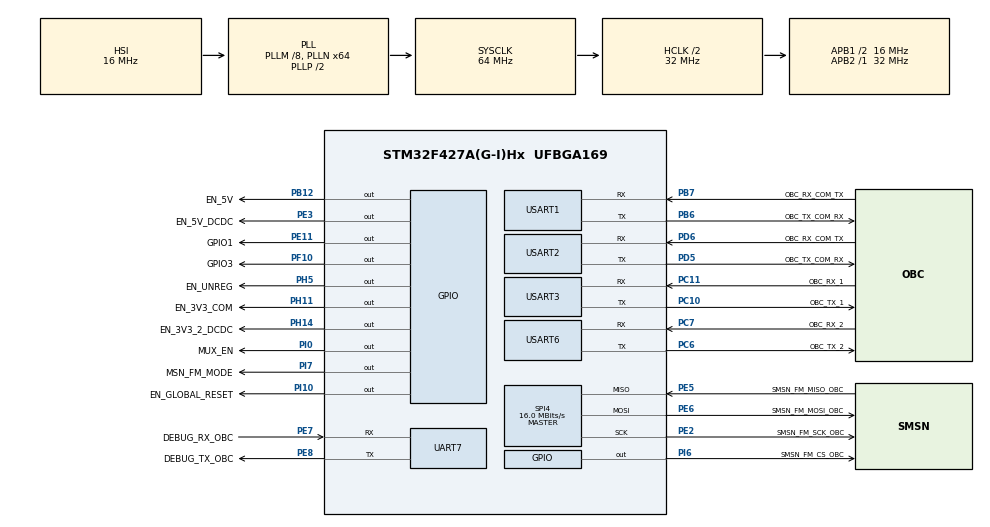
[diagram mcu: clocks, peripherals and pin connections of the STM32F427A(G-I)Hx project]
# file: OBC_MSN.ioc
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Mcu.Family=STM32F4
Mcu.Name=STM32F427A(G-I)Hx
Mcu.Package=UFBGA169
NVIC.PriorityGroup=NVIC_PRIORITYGROUP_4
NVIC.USART1_IRQn=true\:0\:0\:false\:false\:true\:true\:true\:true
NVIC.USART2_IRQn=true\:0\:0\:false\:false\:true\:true\:true\:true
PA13.Mode=Serial_Wire
PA13.Signal=SYS_JTMS-SWDIO
PA14.Mode=Serial_Wire
PA14.Signal=SYS_JTCK-SWCLK
PB12.GPIO_Label=EN_5V
PB12.Signal=GPIO_Output
PB6.GPIO_Label=OBC_TX_COM_RX
PB6.Mode=Asynchronous
PB6.Signal=USART1_TX
PB7.GPIO_Label=OBC_RX_COM_TX
PB7.Mode=Asynchronous
PB7.Signal=USART1_RX
PC10.GPIO_Label=OBC_TX_1
PC10.Mode=Asynchronous
PC10.Signal=USART3_TX
PC11.GPIO_Label=OBC_RX_1
PC11.Mode=Asynchronous
PC11.Signal=USART3_RX
PC6.GPIO_Label=OBC_TX_2
PC6.Mode=Asynchronous
PC6.Signal=USART6_TX
PC7.GPIO_Label=OBC_RX_2
PC7.Mode=Asynchronous
PC7.Signal=USART6_RX
PD5.GPIO_Label=OBC_TX_COM_RX
PD5.Mode=Asynchronous
PD5.Signal=USART2_TX
PD6.GPIO_Label=OBC_RX_COM_TX
PD6.Mode=Asynchronous
PD6.Signal=USART2_RX
PE11.GPIO_Label=GPIO1
PE11.Signal=GPIO_Output
PE2.GPIO_Label=SMSN_FM_SCK_OBC
PE2.Mode=Full_Duplex_Master
PE2.Signal=SPI4_SCK
PE3.GPIO_Label=EN_5V_DCDC
PE3.Signal=GPIO_Output
PE5.GPIO_Label=SMSN_FM_MISO_OBC
PE5.Mode=Full_Duplex_Master
PE5.Signal=SPI4_MISO
PE6.GPIO_Label=SMSN_FM_MOSI_OBC
PE6.Mode=Full_Duplex_Master
PE6.Signal=SPI4_MOSI
PE7.GPIO_Label=DEBUG_RX_OBC
PE7.Mode=Asynchronous
PE7.Signal=UART7_RX
PE8.GPIO_Label=DEBUG_TX_OBC
PE8.Mode=Asynchronous
PE8.Signal=UART7_TX
PF10.GPIO_Label=GPIO3
PF10.Signal=GPIO_Output
PH0/OSC_IN.Mode=HSE-External-Oscillator
PH0/OSC_IN.Signal=RCC_OSC_IN
PH1/OSC_OUT.Mode=HSE-External-Oscillator
PH1/OSC_OUT.Signal=RCC_OSC_OUT
PH11.GPIO_Label=EN_3V3_COM
PH11.Signal=GPIO_Output
PH14.GPIO_Label=EN_3V3_2_DCDC
PH14.Signal=GPIO_Output
PH5.GPIO_Label=EN_UNREG
PH5.Signal=GPIO_Output
PI0.GPIO_Label=MUX_EN
PI0.Signal=GPIO_Output
PI10.GPIO_Label=EN_GLOBAL_RESET
PI10.Signal=GPIO_Output
PI6.GPIO_Label=SMSN_FM_CS_OBC
PI6.Signal=GPIO_Output
PI7.GPIO_Label=MSN_FM_MODE
PI7.Signal=GPIO_Output
ProjectManager.HeapSize=0x200
ProjectManager.StackSize=0x400
ProjectManager.TargetToolchain=STM32CubeIDE
RCC.48MHZClocksFreq_Value=32000000
RCC.AHBCLKDivider=RCC_SYSCLK_DIV2
RCC.AHBFreq_Value=32000000
RCC.APB1CLKDivider=RCC_HCLK_DIV2
RCC.APB1Freq_Value=16000000
RCC.APB1TimFreq_Value=32000000
RCC.APB2Freq_Value=32000000
RCC.APB2TimFreq_Value=32000000
RCC.CortexFreq_Value=32000000
RCC.HCLKFreq_Value=32000000
RCC.HSE_VALUE=24000000
RCC.PLLM=8
RCC.PLLN=64
RCC.SYSCLKFreq_VALUE=64000000
RCC.SYSCLKSource=RCC_SYSCLKSOURCE_PLLCLK
RCC.VCOOutputFreq_Value=128000000
SPI4.CalculateBaudRate=16.0 MBits/s
SPI4.Direction=SPI_DIRECTION_2LINES
SPI4.Mode=SPI_MODE_MASTER
SPI4.VirtualType=VM_MASTER
UART7.VirtualMode=Asynchronous
USART1.VirtualMode=VM_ASYNC
USART2.VirtualMode=VM_ASYNC
USART3.VirtualMode=VM_ASYNC
USART6.VirtualMode=VM_ASYNC
board=custom

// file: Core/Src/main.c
/* USER CODE BEGIN Header */
/**
 ******************************************************************************
 * @file           : main.c
 * @brief          : Main program body
 ******************************************************************************
 * @attention
 *
 * Copyright (c) 2026 STMicroelectronics.
 * All rights reserved.
 *
 * This software is licensed under terms that can be found in the LICENSE file
 * in the root directory of this software component.
 * If no LICENSE file comes with this software, it is provided AS-IS.
 *
 ******************************************************************************
 */
/* USER CODE END Header */
#include "main.h"

/* USER CODE BEGIN Includes */
#include "obc_msn_logic.h"  // <-- ADDED HEADER
/* USER CODE END Includes */

SPI_HandleTypeDef hspi4;

UART_HandleTypeDef huart7;
UART_HandleTypeDef huart1;
UART_HandleTypeDef huart2;
UART_HandleTypeDef huart3;
UART_HandleTypeDef huart6;

void SystemClock_Config(void);
static void MX_GPIO_Init(void);
static void MX_UART7_Init(void);
static void MX_USART1_UART_Init(void);
static void MX_USART2_UART_Init(void);
static void MX_USART3_UART_Init(void);
static void MX_USART6_UART_Init(void);
static void MX_SPI4_Init(void);

int main(void)
{

  /* MCU Configuration--------------------------------------------------------*/

  /* Reset of all peripherals, Initializes the Flash interface and the Systick. */
  HAL_Init();

  /* Configure the system clock */
  SystemClock_Config();

  /* Initialize all configured peripherals */
  MX_GPIO_Init();
  MX_UART7_Init();
  MX_USART1_UART_Init();
  MX_USART2_UART_Init();
  MX_USART3_UART_Init();
  MX_USART6_UART_Init();
  MX_SPI4_Init();
  /* USER CODE BEGIN 2 */
	OBC_Logic_Init();   // <-- ADDED INIT FUNCTION
  /* USER CODE END 2 */

  /* Infinite loop */
	while (1) {

    /* USER CODE BEGIN 3 */
		OBC_Logic_Process(); // <-- ADDED PROCESS LOOP
	}
  /* USER CODE END 3 */
}

void SystemClock_Config(void)
{
  RCC_OscInitTypeDef RCC_OscInitStruct = {0};
  RCC_ClkInitTypeDef RCC_ClkInitStruct = {0};

  /** Configure the main internal regulator output voltage
  */
  __HAL_RCC_PWR_CLK_ENABLE();
  __HAL_PWR_VOLTAGESCALING_CONFIG(PWR_REGULATOR_VOLTAGE_SCALE3);

  /** Initializes the RCC Oscillators according to the specified parameters
  * in the RCC_OscInitTypeDef structure.
  */
  RCC_OscInitStruct.OscillatorType = RCC_OSCILLATORTYPE_HSI;
  RCC_OscInitStruct.HSIState = RCC_HSI_ON;
  RCC_OscInitStruct.HSICalibrationValue = RCC_HSICALIBRATION_DEFAULT;
  RCC_OscInitStruct.PLL.PLLState = RCC_PLL_ON;
  RCC_OscInitStruct.PLL.PLLSource = RCC_PLLSOURCE_HSI;
  RCC_OscInitStruct.PLL.PLLM = 8;
  RCC_OscInitStruct.PLL.PLLN = 64;
  RCC_OscInitStruct.PLL.PLLP = RCC_PLLP_DIV2;
  RCC_OscInitStruct.PLL.PLLQ = 4;
  if (HAL_RCC_OscConfig(&RCC_OscInitStruct) != HAL_OK)
  {
    Error_Handler();
  }

  /** Initializes the CPU, AHB and APB buses clocks
  */
  RCC_ClkInitStruct.ClockType = RCC_CLOCKTYPE_HCLK|RCC_CLOCKTYPE_SYSCLK
                              |RCC_CLOCKTYPE_PCLK1|RCC_CLOCKTYPE_PCLK2;
  RCC_ClkInitStruct.SYSCLKSource = RCC_SYSCLKSOURCE_PLLCLK;
  RCC_ClkInitStruct.AHBCLKDivider = RCC_SYSCLK_DIV2;
  RCC_ClkInitStruct.APB1CLKDivider = RCC_HCLK_DIV2;
  RCC_ClkInitStruct.APB2CLKDivider = RCC_HCLK_DIV1;

  if (HAL_RCC_ClockConfig(&RCC_ClkInitStruct, FLASH_LATENCY_1) != HAL_OK)
  {
    Error_Handler();
  }
}

static void MX_SPI4_Init(void)
{

  /* SPI4 parameter configuration*/
  hspi4.Instance = SPI4;
  hspi4.Init.Mode = SPI_MODE_MASTER;
  hspi4.Init.Direction = SPI_DIRECTION_2LINES;
  hspi4.Init.DataSize = SPI_DATASIZE_8BIT;
  hspi4.Init.CLKPolarity = SPI_POLARITY_LOW;
  hspi4.Init.CLKPhase = SPI_PHASE_1EDGE;
  hspi4.Init.NSS = SPI_NSS_SOFT;
  hspi4.Init.BaudRatePrescaler = SPI_BAUDRATEPRESCALER_2;
  hspi4.Init.FirstBit = SPI_FIRSTBIT_MSB;
  hspi4.Init.TIMode = SPI_TIMODE_DISABLE;
  hspi4.Init.CRCCalculation = SPI_CRCCALCULATION_DISABLE;
  hspi4.Init.CRCPolynomial = 10;
  if (HAL_SPI_Init(&hspi4) != HAL_OK)
  {
    Error_Handler();
  }

}

static void MX_UART7_Init(void)
{

  huart7.Instance = UART7;
  huart7.Init.BaudRate = 115200;
  huart7.Init.WordLength = UART_WORDLENGTH_8B;
  huart7.Init.StopBits = UART_STOPBITS_1;
  huart7.Init.Parity = UART_PARITY_NONE;
  huart7.Init.Mode = UART_MODE_TX_RX;
  huart7.Init.HwFlowCtl = UART_HWCONTROL_NONE;
  huart7.Init.OverSampling = UART_OVERSAMPLING_16;
  if (HAL_UART_Init(&huart7) != HAL_OK)
  {
    Error_Handler();
  }

}

static void MX_USART1_UART_Init(void)
{

  huart1.Instance = USART1;
  huart1.Init.BaudRate = 115200;
  huart1.Init.WordLength = UART_WORDLENGTH_8B;
  huart1.Init.StopBits = UART_STOPBITS_1;
  huart1.Init.Parity = UART_PARITY_NONE;
  huart1.Init.Mode = UART_MODE_TX_RX;
  huart1.Init.HwFlowCtl = UART_HWCONTROL_NONE;
  huart1.Init.OverSampling = UART_OVERSAMPLING_16;
  if (HAL_UART_Init(&huart1) != HAL_OK)
  {
    Error_Handler();
  }

}

static void MX_USART2_UART_Init(void)
{

  huart2.Instance = USART2;
  huart2.Init.BaudRate = 115200;
  huart2.Init.WordLength = UART_WORDLENGTH_8B;
  huart2.Init.StopBits = UART_STOPBITS_1;
  huart2.Init.Parity = UART_PARITY_NONE;
  huart2.Init.Mode = UART_MODE_TX_RX;
  huart2.Init.HwFlowCtl = UART_HWCONTROL_NONE;
  huart2.Init.OverSampling = UART_OVERSAMPLING_16;
  if (HAL_UART_Init(&huart2) != HAL_OK)
  {
    Error_Handler();
  }

}

static void MX_USART3_UART_Init(void)
{

  huart3.Instance = USART3;
  huart3.Init.BaudRate = 115200;
  huart3.Init.WordLength = UART_WORDLENGTH_8B;
  huart3.Init.StopBits = UART_STOPBITS_1;
  huart3.Init.Parity = UART_PARITY_NONE;
  huart3.Init.Mode = UART_MODE_TX_RX;
  huart3.Init.HwFlowCtl = UART_HWCONTROL_NONE;
  huart3.Init.OverSampling = UART_OVERSAMPLING_16;
  if (HAL_UART_Init(&huart3) != HAL_OK)
  {
    Error_Handler();
  }

}

static void MX_USART6_UART_Init(void)
{

  huart6.Instance = USART6;
  huart6.Init.BaudRate = 115200;
  huart6.Init.WordLength = UART_WORDLENGTH_8B;
  huart6.Init.StopBits = UART_STOPBITS_1;
  huart6.Init.Parity = UART_PARITY_NONE;
  huart6.Init.Mode = UART_MODE_TX_RX;
  huart6.Init.HwFlowCtl = UART_HWCONTROL_NONE;
  huart6.Init.OverSampling = UART_OVERSAMPLING_16;
  if (HAL_UART_Init(&huart6) != HAL_OK)
  {
    Error_Handler();
  }

}

static void MX_GPIO_Init(void)
{
  GPIO_InitTypeDef GPIO_InitStruct = {0};

  /* GPIO Ports Clock Enable */
  __HAL_RCC_GPIOI_CLK_ENABLE();
  __HAL_RCC_GPIOA_CLK_ENABLE();
  __HAL_RCC_GPIOE_CLK_ENABLE();
  __HAL_RCC_GPIOB_CLK_ENABLE();
  __HAL_RCC_GPIOD_CLK_ENABLE();
  __HAL_RCC_GPIOC_CLK_ENABLE();
  __HAL_RCC_GPIOH_CLK_ENABLE();
  __HAL_RCC_GPIOF_CLK_ENABLE();

  /*Configure GPIO pin Output Level */
  HAL_GPIO_WritePin(GPIOI, SMSN_FM_CS_OBC_Pin|MSN_FM_MODE_Pin|MUX_EN_Pin|EN_GLOBAL_RESET_Pin, GPIO_PIN_RESET);

  /*Configure GPIO pin Output Level */
  HAL_GPIO_WritePin(GPIOE, EN_5V_DCDC_Pin|GPIO1_Pin, GPIO_PIN_RESET);

  /*Configure GPIO pin Output Level */
  HAL_GPIO_WritePin(GPIOH, EN_3V3_2_DCDC_Pin|EN_UNREG_Pin|EN_3V3_COM_Pin, GPIO_PIN_RESET);

  /*Configure GPIO pin Output Level */
  HAL_GPIO_WritePin(GPIO3_GPIO_Port, GPIO3_Pin, GPIO_PIN_RESET);

  /*Configure GPIO pin Output Level */
  HAL_GPIO_WritePin(EN_5V_GPIO_Port, EN_5V_Pin, GPIO_PIN_RESET);

  /*Configure GPIO pins : SMSN_FM_CS_OBC_Pin MSN_FM_MODE_Pin MUX_EN_Pin EN_GLOBAL_RESET_Pin */
  GPIO_InitStruct.Pin = SMSN_FM_CS_OBC_Pin|MSN_FM_MODE_Pin|MUX_EN_Pin|EN_GLOBAL_RESET_Pin;
  GPIO_InitStruct.Mode = GPIO_MODE_OUTPUT_PP;
  GPIO_InitStruct.Pull = GPIO_NOPULL;
  GPIO_InitStruct.Speed = GPIO_SPEED_FREQ_LOW;
  HAL_GPIO_Init(GPIOI, &GPIO_InitStruct);

  /*Configure GPIO pins : EN_5V_DCDC_Pin GPIO1_Pin */
  GPIO_InitStruct.Pin = EN_5V_DCDC_Pin|GPIO1_Pin;
  GPIO_InitStruct.Mode = GPIO_MODE_OUTPUT_PP;
  GPIO_InitStruct.Pull = GPIO_NOPULL;
  GPIO_InitStruct.Speed = GPIO_SPEED_FREQ_LOW;
  HAL_GPIO_Init(GPIOE, &GPIO_InitStruct);

  /*Configure GPIO pins : EN_3V3_2_DCDC_Pin EN_UNREG_Pin EN_3V3_COM_Pin */
  GPIO_InitStruct.Pin = EN_3V3_2_DCDC_Pin|EN_UNREG_Pin|EN_3V3_COM_Pin;
  GPIO_InitStruct.Mode = GPIO_MODE_OUTPUT_PP;
  GPIO_InitStruct.Pull = GPIO_NOPULL;
  GPIO_InitStruct.Speed = GPIO_SPEED_FREQ_LOW;
  HAL_GPIO_Init(GPIOH, &GPIO_InitStruct);

  /*Configure GPIO pin : GPIO3_Pin */
  GPIO_InitStruct.Pin = GPIO3_Pin;
  GPIO_InitStruct.Mode = GPIO_MODE_OUTPUT_PP;
  GPIO_InitStruct.Pull = GPIO_NOPULL;
  GPIO_InitStruct.Speed = GPIO_SPEED_FREQ_LOW;
  HAL_GPIO_Init(GPIO3_GPIO_Port, &GPIO_InitStruct);

  /*Configure GPIO pin : EN_5V_Pin */
  GPIO_InitStruct.Pin = EN_5V_Pin;
  GPIO_InitStruct.Mode = GPIO_MODE_OUTPUT_PP;
  GPIO_InitStruct.Pull = GPIO_NOPULL;
  GPIO_InitStruct.Speed = GPIO_SPEED_FREQ_LOW;
  HAL_GPIO_Init(EN_5V_GPIO_Port, &GPIO_InitStruct);

}

void Error_Handler(void)
{
	__disable_irq();
	while (1) {
	}
}
